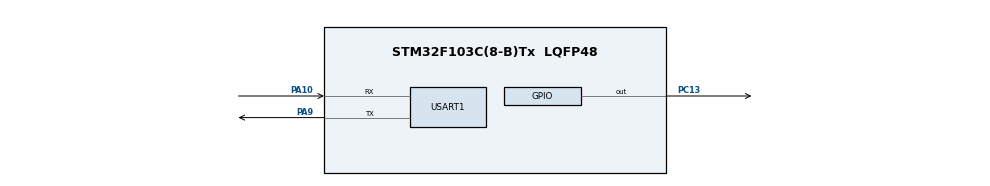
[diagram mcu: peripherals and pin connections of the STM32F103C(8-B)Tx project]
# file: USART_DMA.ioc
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Dma.Request0=USART1_RX
Dma.Request1=USART1_TX
Dma.USART1_RX.0.Direction=DMA_PERIPH_TO_MEMORY
Dma.USART1_RX.0.Instance=DMA1_Channel5
Dma.USART1_RX.0.MemDataAlignment=DMA_MDATAALIGN_BYTE
Dma.USART1_RX.0.MemInc=DMA_MINC_ENABLE
Dma.USART1_RX.0.Mode=DMA_CIRCULAR
Dma.USART1_RX.0.PeriphDataAlignment=DMA_PDATAALIGN_BYTE
Dma.USART1_RX.0.PeriphInc=DMA_PINC_DISABLE
Dma.USART1_RX.0.Priority=DMA_PRIORITY_MEDIUM
Dma.USART1_TX.1.Direction=DMA_MEMORY_TO_PERIPH
Dma.USART1_TX.1.Instance=DMA1_Channel4
Dma.USART1_TX.1.MemDataAlignment=DMA_MDATAALIGN_BYTE
Dma.USART1_TX.1.MemInc=DMA_MINC_ENABLE
Dma.USART1_TX.1.Mode=DMA_CIRCULAR
Dma.USART1_TX.1.PeriphDataAlignment=DMA_PDATAALIGN_BYTE
Dma.USART1_TX.1.PeriphInc=DMA_PINC_DISABLE
Dma.USART1_TX.1.Priority=DMA_PRIORITY_MEDIUM
Mcu.Family=STM32F1
Mcu.Name=STM32F103C(8-B)Tx
Mcu.Package=LQFP48
NVIC.DMA1_Channel4_IRQn=true\:0\:0\:false\:false\:true\:false\:true
NVIC.DMA1_Channel5_IRQn=true\:0\:0\:false\:false\:true\:false\:true
NVIC.PriorityGroup=NVIC_PRIORITYGROUP_4
NVIC.USART1_IRQn=true\:0\:0\:false\:false\:true\:true\:true
PA10.Mode=Asynchronous
PA10.Signal=USART1_RX
PA13.Mode=Trace_Asynchronous_SW
PA13.Signal=SYS_JTMS-SWDIO
PA14.Mode=Trace_Asynchronous_SW
PA14.Signal=SYS_JTCK-SWCLK
PA9.Mode=Asynchronous
PA9.Signal=USART1_TX
PB3.Mode=Trace_Asynchronous_SW
PB3.Signal=SYS_JTDO-TRACESWO
PC13-TAMPER-RTC.Signal=GPIO_Output
ProjectManager.HeapSize=0x200
ProjectManager.StackSize=0x400
ProjectManager.TargetToolchain=Makefile
RCC.APB1Freq_Value=8000000
RCC.APB2Freq_Value=8000000
USART1.VirtualMode=VM_ASYNC
board=custom

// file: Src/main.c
/* USER CODE BEGIN Header */
/**
  ******************************************************************************
  * @file           : main.c
  * @brief          : Main program body
  ******************************************************************************
  * @attention
  *
  * <h2><center>&copy; Copyright (c) 2020 STMicroelectronics.
  * All rights reserved.</center></h2>
  *
  * This software component is licensed by ST under BSD 3-Clause license,
  * the "License"; You may not use this file except in compliance with the
  * License. You may obtain a copy of the License at:
  *                        opensource.org/licenses/BSD-3-Clause
  *
  ******************************************************************************
  */
/* USER CODE END Header */
#include "main.h"
#include "dma.h"
#include "usart.h"
#include "gpio.h"

/* USER CODE BEGIN Includes */
#include <stdio.h>
/* USER CODE END Includes */

/* USER CODE BEGIN PV */
uint8_t Usart1_RxBuff[BUFFLEN];
uint8_t Usart1_TxBuff[BUFFLEN];
/* USER CODE END PV */

void SystemClock_Config(void);

/* USER CODE BEGIN 0 */

void Activate_DMA(void)
{
  LL_USART_EnableDMAReq_TX(USART1);
  LL_DMA_ConfigAddresses(DMA1, LL_DMA_CHANNEL_4,
                         (uint32_t)(Usart1_TxBuff),
                         LL_USART_DMA_GetRegAddr(USART1),
                         LL_DMA_GetDataTransferDirection(DMA1, LL_DMA_CHANNEL_4));
  LL_DMA_SetDataLength(DMA1, LL_DMA_CHANNEL_4, BUFFLEN);
  LL_DMA_EnableChannel(DMA1, LL_DMA_CHANNEL_4);

  LL_USART_EnableDMAReq_RX(USART1);
  LL_DMA_ConfigAddresses(DMA1, LL_DMA_CHANNEL_5,
                         LL_USART_DMA_GetRegAddr(USART1),
                         (uint32_t)(Usart1_RxBuff),
                         LL_DMA_GetDataTransferDirection(DMA1, LL_DMA_CHANNEL_5));
  LL_DMA_SetDataLength(DMA1, LL_DMA_CHANNEL_5, BUFFLEN);
  LL_DMA_EnableChannel(DMA1, LL_DMA_CHANNEL_5);
}

void DMA1_Channel4_Callback(void)
{
  LL_DMA_DisableChannel(DMA1, LL_DMA_CHANNEL_4);
  LL_DMA_ConfigAddresses(DMA1, LL_DMA_CHANNEL_4,
                         (uint32_t)(Usart1_TxBuff),
                         LL_USART_DMA_GetRegAddr(USART1),
                         LL_DMA_GetDataTransferDirection(DMA1, LL_DMA_CHANNEL_4));
  LL_DMA_SetDataLength(DMA1, LL_DMA_CHANNEL_4, BUFFLEN);
}

void DMA1_Channel5_Callback(uint32_t Lenth)
{
  static uint16_t Remain = BUFFLEN;

  for (uint16_t i = BUFFLEN - Remain; i != BUFFLEN - Lenth;)
  {
    Usart1_TxBuff[i] = Usart1_RxBuff[i];
    if (++i == BUFFLEN)
    {
      LL_DMA_EnableChannel(DMA1, LL_DMA_CHANNEL_4);
      i = 0;
    }
  }

  Remain = Lenth;
}

/* USER CODE END 0 */

int main(void)
{

  /* MCU Configuration--------------------------------------------------------*/

  /* Reset of all peripherals, Initializes the Flash interface and the Systick. */

  LL_APB2_GRP1_EnableClock(LL_APB2_GRP1_PERIPH_AFIO);
  LL_APB1_GRP1_EnableClock(LL_APB1_GRP1_PERIPH_PWR);

  NVIC_SetPriorityGrouping(NVIC_PRIORITYGROUP_4);

  /* System interrupt init*/

  /** NOJTAG: JTAG-DP Disabled and SW-DP Enabled
  */
  LL_GPIO_AF_Remap_SWJ_NOJTAG();

  /* Configure the system clock */
  SystemClock_Config();

  /* Initialize all configured peripherals */
  MX_GPIO_Init();
  MX_DMA_Init();
  MX_USART1_UART_Init();
  /* USER CODE BEGIN 2 */
  Configure_DMA();
  Configure_USART();
  Activate_DMA();
  printf("OK\r\n");
  /* USER CODE END 2 */

  /* Infinite loop */
  while (1)
  {

    /* USER CODE BEGIN 3 */
    LL_mDelay(1000);
    LL_GPIO_TogglePin(GPIOC, LL_GPIO_PIN_13);
  }
  /* USER CODE END 3 */
}

void SystemClock_Config(void)
{
  LL_FLASH_SetLatency(LL_FLASH_LATENCY_0);
  while(LL_FLASH_GetLatency()!= LL_FLASH_LATENCY_0)
  {
  }
  LL_RCC_HSI_SetCalibTrimming(16);
  LL_RCC_HSI_Enable();

   /* Wait till HSI is ready */
  while(LL_RCC_HSI_IsReady() != 1)
  {

  }
  LL_RCC_SetAHBPrescaler(LL_RCC_SYSCLK_DIV_1);
  LL_RCC_SetAPB1Prescaler(LL_RCC_APB1_DIV_1);
  LL_RCC_SetAPB2Prescaler(LL_RCC_APB2_DIV_1);
  LL_RCC_SetSysClkSource(LL_RCC_SYS_CLKSOURCE_HSI);

   /* Wait till System clock is ready */
  while(LL_RCC_GetSysClkSource() != LL_RCC_SYS_CLKSOURCE_STATUS_HSI)
  {

  }
  LL_Init1msTick(8000000);
  LL_SetSystemCoreClock(8000000);
}

void Error_Handler(void)
{
}

/************************ (C) COPYRIGHT STMicroelectronics *****END OF FILE****/
